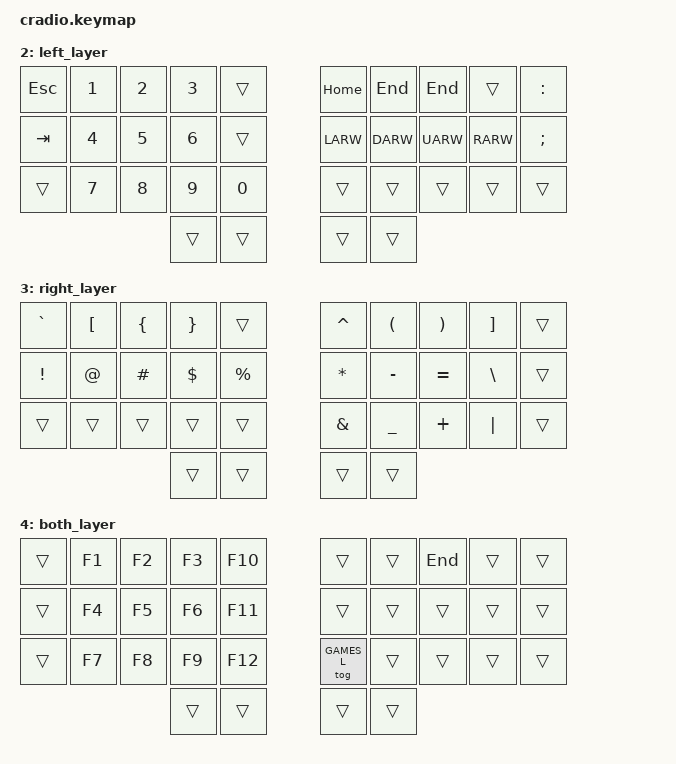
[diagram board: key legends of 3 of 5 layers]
// Copyright (c) 2022 The ZMK Contributors
// SPDX-License-Identifier: MIT

#include <behaviors.dtsi>
#include <dt-bindings/zmk/keys.h>
#include <dt-bindings/zmk/bt.h>

// Layer Names
#define DEFAULT_L 0
#define GAMES_L   1
#define LEFT_L    2
#define RIGHT_L   3
#define BOTH_L    4

// Home row mods macro
#define HRML(k1,k2,k3,k4) &ht LSHFT k1  &ht LALT k2  &ht LCTRL k3  &ht LGUI k4
#define HRMR(k1,k2,k3,k4) &ht RGUI k1  &ht RCTRL k2  &ht RALT k3  &ht RSHFT k4

/ {
    behaviors {
        ht: hold_tap {
            label = "hold_tap";
            compatible = "zmk,behavior-hold-tap";
            #binding-cells = <2>;
            flavor = "balanced";
            tapping-term-ms = <200>;
            // quick-tap-ms = <250>;
            // global-quick-tap;
            bindings = <&kp>, <&kp>;
        };
    };

    conditional_layers {
        compatible = "zmk,conditional-layers";
        tri_layer {
            if-layers = <LEFT_L RIGHT_L>;
            then-layer = <BOTH_L>;
        };
    };

    keymap {
        compatible = "zmk,keymap";
        // 0
        default_layer {
            bindings = <
        //╭──────────┬──────────┬──────────┬──────────┬──────────╮   ╭──────────┬──────────┬──────────┬──────────┬──────────╮
        //│  Q       │  W       │  E       │  R       │  T       │   │  Y       │  U       │  I       │  O       │  P       │
            &kp Q      &kp W      &kp E      &kp R      &kp T          &kp Y      &kp U      &kp I      &kp O      &kp P
        //├──────────┼──────────┼──────────┼──────────┼──────────┤   ├──────────┼──────────┼──────────┼──────────┼──────────┤
        //│  A       │  S       │  D       │  F       │  G       │   │  H       │  J       │  K       │  L       │ ' "      │
            HRML(A,        S,         D,         F)     &kp G          &kp H      HRMR(J,        K,         L,        SQT)
        //├──────────┼──────────┼──────────┼──────────┼──────────┤   ├──────────┼──────────┼──────────┼──────────┼──────────┤
        //│  Z       │  X       │  C       │  V       │  B       │   │  N       │  M       │ , <      │ . >      │ / ?      │
            &kp Z      &kp X      &kp C      &kp V      &kp B          &kp N      &kp M      &kp COMMA  &kp DOT    &kp FSLH
        //╰──────────┴──────────┴──────────┼──────────┼──────────┤   ├──────────┼──────────┼──────────┴──────────┴──────────╯
                                        &kp BSPC  &lt LEFT_L SPACE  &lt RIGHT_L ENTER  &kp DEL
        //                                 ╰──────────┴──────────╯   ╰──────────┴──────────╯
            >;
        };

        // 1
        // I (Sam Levoir) was having trouble playing games with the home row mods, so heres this layer just for games.
        games_layer {
            bindings = <
        //╭──────────┬──────────┬──────────┬──────────┬──────────╮   ╭──────────┬──────────┬──────────┬──────────┬──────────╮
        //│  Q       │  W       │  E       │  R       │  T       │   │  Y       │  U       │  I       │  O       │  P       │
            &kp Q      &kp W      &kp E      &kp R      &kp T          &kp Y      &kp U      &kp I      &kp O      &kp P
        //├──────────┼──────────┼──────────┼──────────┼──────────┤   ├──────────┼──────────┼──────────┼──────────┼──────────┤
        //│  A       │  S       │  D       │  F       │  G       │   │  H       │  J       │  K       │  L       │ ' "      │
            &kp A      &kp S      &kp D      &kp F      &kp G          &kp H      HRMR(J,        K,         L,        SQT)
        //├──────────┼──────────┼──────────┼──────────┼──────────┤   ├──────────┼──────────┼──────────┼──────────┼──────────┤
        //│  Z       │  X       │  C       │  V       │  B       │   │  N       │  M       │ , <      │ . >      │ / ?      │
            &kp Z      &kp X      &kp C      &kp V      &kp B          &kp N      &kp M      &kp COMMA  &kp DOT    &kp FSLH
        //╰──────────┴──────────┴──────────┼──────────┼──────────┤   ├──────────┼──────────┼──────────┴──────────┴──────────╯
                                            &kp LALT    &kp SPACE  &lt RIGHT_L ENTER  &lt LEFT_L DEL
        //                                 ╰──────────┴──────────╯   ╰──────────┴──────────╯
            >;
        };

        // 2
        left_layer {
            bindings = <
        //╭──────────┬──────────┬──────────┬──────────┬──────────╮   ╭──────────┬──────────┬──────────┬──────────┬──────────╮
        //│  ESC     │  1       │  2       │  3       │          │   │ HOME     │ END      │          │          │  :       │
            &kp ESC    &kp N1     &kp N2     &kp N3     &trans         &kp HOME   &kp END    &kp END    &trans    &kp COLON
        //├──────────┼──────────┼──────────┼──────────┼──────────┤   ├──────────┼──────────┼──────────┼──────────┼──────────┤
        //│  TAB     │  4       │  5       │  6       │          │   │ LEFT     │ DOWN     │ UP       │ RIGHT    │  ;       │
            &kp TAB    &kp N4     &kp N5     &kp N6     &trans         &kp LARW   &kp DARW   &kp UARW   &kp RARW   &kp SEMI
        //├──────────┼──────────┼──────────┼──────────┼──────────┤   ├──────────┼──────────┼──────────┼──────────┼──────────┤
        //│          │  7       │  8       │  9       │  0       │   │          │          │          │          │          │
            &trans     &kp N7     &kp N8     &kp N9     &kp N0         &trans     &trans     &trans     &trans     &trans
        //╰──────────┴──────────┴──────────┼──────────┼──────────┤   ├──────────┼──────────┼──────────┴──────────┴──────────╯
                                              &trans     &trans         &trans     &trans
        //                                 ╰──────────┴──────────╯   ╰──────────┴──────────╯
            >;
        };

        // 3
        right_layer {
            bindings = <
        //╭──────────┬──────────┬──────────┬──────────┬──────────╮   ╭──────────┬──────────┬──────────┬──────────┬──────────╮
        //│  ` ~     │  [       │  {       │  }       │          │   │  ^       │  (       │  )       │  ]       │          │
            &kp GRAVE  &kp LBKT   &kp LBRC   &kp RBRC   &trans         &kp CARET  &kp LPAR   &kp RPAR   &kp RBKT   &trans
        //├──────────┼──────────┼──────────┼──────────┼──────────┤   ├──────────┼──────────┼──────────┼──────────┼──────────┤
        //│  !       │  @       │  #       │  $       │  %       │   │  *       │  -       │  =       │  \       │          │
            &kp EXCL   &kp AT     &kp HASH   &kp DLLR   &kp PRCNT      &kp ASTRK  &kp MINUS  &kp EQUAL  &kp BSLH   &trans
        //├──────────┼──────────┼──────────┼──────────┼──────────┤   ├──────────┼──────────┼──────────┼──────────┼──────────┤
        //│          │          │          │          │          │   │  &       │  _       │  +       │  │       │          │
            &trans     &trans     &trans     &trans     &trans         &kp AMPS   &kp UNDER  &kp PLUS   &kp PIPE   &trans
        //╰──────────┴──────────┴──────────┼──────────┼──────────┤   ├──────────┼──────────┼──────────┴──────────┴──────────╯
                                              &trans     &trans         &trans     &trans
        //                                 ╰──────────┴──────────╯   ╰──────────┴──────────╯
            >;
        };

        // 4
        both_layer {
            bindings = <
        //╭──────────┬──────────┬──────────┬──────────┬──────────╮   ╭──────────┬──────────┬──────────┬──────────┬──────────╮
        //│          │   F1     │  F2      │  F3      │  F10     │   │          │          │          │          │          │
            &trans     &kp F1     &kp F2     &kp F3     &kp F10        &trans     &trans     &kp END    &trans     &trans
        //├──────────┼──────────┼──────────┼──────────┼──────────┤   ├──────────┼──────────┼──────────┼──────────┼──────────┤
        //│          │   F4     │  F5      │  F6      │  F11     │   │          │          │          │          │          │
            &trans     &kp F4     &kp F5     &kp F6     &kp F11        &trans     &trans     &trans     &trans     &trans
        //├──────────┼──────────┼──────────┼──────────┼──────────┤   ├──────────┼──────────┼──────────┼──────────┼──────────┤
        //│          │   F7     │  F8      │  F9      │  F12     │   │ Game Tog │          │          │          │          │
            &trans     &kp F7     &kp F8     &kp F9     &kp F12      &tog GAMES_L &trans     &trans     &trans     &trans
        //╰──────────┴──────────┴──────────┼──────────┼──────────┤   ├──────────┼──────────┼──────────┴──────────┴──────────╯
                                              &trans     &trans         &trans     &trans
        //                                 ╰──────────┴──────────╯   ╰──────────┴──────────╯
            >;
        };

    };
};
